# MKL28T7_CORE0 register map
Vendor: Freescale Semiconductor, Inc.; Series: Kinetis_L; File version: 1.6
CPU: CM0PLUS r0p0, little endian, no MPU, no FPU, VTOR, 2 interrupt priority bits
Registers are 32-bit, read-write, reset 0x0 unless marked. A register's access mark holds for its fields unless they carry their own. Offsets are from the block's base; [hi:lo] are bit positions; {n}, {i} and the like mark numbered series; 'fields as' and 'values as' point back to an identical list.

## TSI0 — Touch sense input
Base 0x40062000; register names take the prefix TSI0_
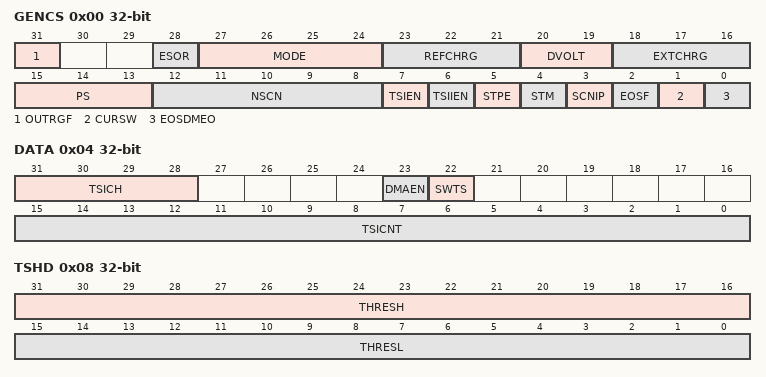
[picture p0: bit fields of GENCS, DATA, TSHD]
0x00 GENCS — TSI General Control and Status Register
  [31] OUTRGF — Out of Range Flag.
  [28] ESOR — End-of-scan or Out-of-Range Interrupt Selection
    0=Out-of-range interrupt is allowed; 1=End-of-scan interrupt is allowed
  [27:24] MODE — TSI analog modes setup and status bits.
    0=Set TSI in capacitive sensing(non-noise detection) mode; 4=Set TSI analog to work in single threshold noise detection mode and the frequency limitation circuit is disabled; 8=Set TSI analog to work in single threshold noise detection mode and the frequency limitation circuit is enabled to work in higher frequencies operations; 12=Set TSI analog to work in automatic noise detection mode
  [23:21] REFCHRG
    0=500 nA; 1=1 uA; 2=2 uA; 3=4 uA; 4=8 uA; 5=16 uA; 6=32 uA; 7=64 uA
  [20:19] DVOLT
    0=DV = 1.026 V; VP = 1.328 V; Vm = 0.302 V; 1=DV = 0.592 V; VP = 1.111 V; Vm = 0.519 V; 2=DV = 0.342 V; VP = 0.986 V; Vm = 0.644 V; 3=DV = 0.197 V; VP = 0.914 V; Vm = 0.716 V
  [18:16] EXTCHRG
    values as REFCHRG
  [15:13] PS
    0=Electrode Oscillator Frequency divided by 1; 1=Electrode Oscillator Frequency divided by 2; 2=Electrode Oscillator Frequency divided by 4; 3=Electrode Oscillator Frequency divided by 8; 4=Electrode Oscillator Frequency divided by 16; 5=Electrode Oscillator Frequency divided by 32; 6=Electrode Oscillator Frequency divided by 64; 7=Electrode Oscillator Frequency divided by 128
  [12:8] NSCN
    0=Once per electrode; 1=Twice per electrode; {v}={v+1} times per electrode (v=2..31)
  [7] TSIEN — Touch Sensing Input Module Enable
    0=TSI module disabled; 1=TSI module enabled
  [6] TSIIEN — Touch Sensing Input Interrupt Enable
    0=TSI interrupt is disabled; 1=TSI interrupt is enabled
  [5] STPE — TSI STOP Enable
    0=TSI is disabled when MCU goes into low power mode; 1=Allows TSI to continue running in all low power modes
  [4] STM — Scan Trigger Mode
    0=Software trigger scan; 1=Hardware trigger scan
  [3] SCNIP ro — Scan In Progress Status
    0=No scan in progress; 1=Scan in progress
  [2] EOSF — End of Scan Flag
    0=Scan not complete; 1=Scan complete
  [1] CURSW
    0=The current source pair are not swapped; 1=The current source pair are swapped
  [0] EOSDMEO — End-of-Scan DMA Transfer Request Enable Only
    0=Do not enable the End-of-Scan DMA transfer request only. Depending on ESOR state, either Out-of-Range or End-of-Scan can trigger a DMA transfer request and interrupt.; 1=Only the End-of-Scan event can trigger a DMA transfer request. The Out-of-Range event only and always triggers an interrupt if TSIIE is set.
0x04 DATA — TSI DATA Register
  [31:28] TSICH
    {v}=Channel {v} (v=0..15)
  [23] DMAEN — DMA Transfer Enabled
    0=Interrupt is selected when the interrupt enable bit is set and the corresponding TSI events assert; 1=DMA transfer request is selected when the interrupt enable bit is set and the corresponding TSI events assert
  [22] SWTS wo — Software Trigger Start
    0=No effect; 1=Start a scan to determine which channel is specified by TSI_DATA[TSICH]
  [15:0] TSICNT ro — TSI Conversion Counter Value
0x08 TSHD — TSI Threshold Register
  [31:16] THRESH — TSI Wakeup Channel High-threshold
  [15:0] THRESL — TSI Wakeup Channel Low-threshold

## DAC0 — 12-Bit Digital-to-Analog Converter
Base 0x4006A000; register names take the prefix DAC0_
{0x0+2i} DAT{i}L (i=0..15) 8-bit — DAC Data Low Register
  [7:0] DATA0
{0x1+2i} DAT{i}H (i=0..15) 8-bit — DAC Data High Register
  [3:0] DATA1
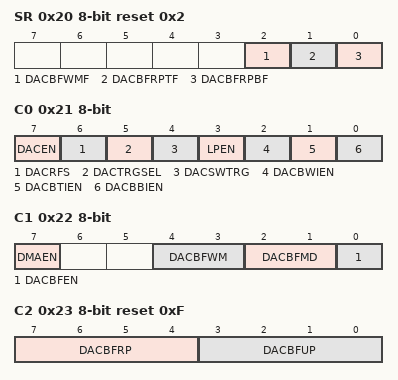
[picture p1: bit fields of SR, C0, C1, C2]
0x20 SR 8-bit reset 0x2 — DAC Status Register
  [2] DACBFWMF — DAC Buffer Watermark Flag
    0=The DAC buffer read pointer has not reached the watermark level; 1=The DAC buffer read pointer has reached the watermark level
  [1] DACBFRPTF — DAC Buffer Read Pointer Top Position Flag
    0=The DAC buffer read pointer is not zero; 1=The DAC buffer read pointer is zero
  [0] DACBFRPBF — DAC Buffer Read Pointer Bottom Position Flag
    0=The DAC buffer read pointer is not equal to C2[DACBFUP]; 1=The DAC buffer read pointer is equal to C2[DACBFUP]
0x21 C0 8-bit — DAC Control Register
  [7] DACEN — DAC Enable
    0=The DAC system is disabled; 1=The DAC system is enabled
  [6] DACRFS — DAC Reference Select
    0=The DAC selects DACREF_1 as the reference voltage; 1=The DAC selects DACREF_2 as the reference voltage
  [5] DACTRGSEL — DAC Trigger Select
    0=The DAC hardware trigger is selected; 1=The DAC software trigger is selected
  [4] DACSWTRG wo — DAC Software Trigger
    0=The DAC soft trigger is not valid; 1=The DAC soft trigger is valid
  [3] LPEN — DAC Low Power Control
    0=High-Power mode; 1=Low-Power mode
  [2] DACBWIEN — DAC Buffer Watermark Interrupt Enable
    0=The DAC buffer watermark interrupt is disabled; 1=The DAC buffer watermark interrupt is enabled
  [1] DACBTIEN — DAC Buffer Read Pointer Top Flag Interrupt Enable
    0=The DAC buffer read pointer top flag interrupt is disabled; 1=The DAC buffer read pointer top flag interrupt is enabled
  [0] DACBBIEN — DAC Buffer Read Pointer Bottom Flag Interrupt Enable
    0=The DAC buffer read pointer bottom flag interrupt is disabled; 1=The DAC buffer read pointer bottom flag interrupt is enabled
0x22 C1 8-bit — DAC Control Register 1
  [7] DMAEN — DMA Enable Select
    0=DMA is disabled; 1=DMA is enabled. When DMA is enabled, the DMA request will be generated by original interrupts. The interrupts will not be presented on this module at the same time.
  [4:3] DACBFWM — DAC Buffer Watermark Select
    0=In normal mode, 1 word . In FIFO mode, 2 or less than 2 data remaining in FIFO will set watermark status bit.; 1=In normal mode, 2 words . In FIFO mode, Max/4 or less than Max/4 data remaining in FIFO will set watermark status bit.; 2=In normal mode, 3 words . In FIFO mode, Max/2 or less than Max/2 data remaining in FIFO will set watermark status bit.; 3=In normal mode, 4 words . In FIFO mode, Max-2 or less than Max-2 data remaining in FIFO will set watermark status bit.
  [2:1] DACBFMD — DAC Buffer Work Mode Select
    0=Normal mode; 1=Swing mode; 2=One-Time Scan mode; 3=FIFO mode
  [0] DACBFEN — DAC Buffer Enable
    0=Buffer read pointer is disabled. The converted data is always the first word of the buffer.; 1=Buffer read pointer is enabled. The converted data is the word that the read pointer points to. It means converted data can be from any word of the buffer.
0x23 C2 8-bit reset 0xF — DAC Control Register 2
  [7:4] DACBFRP — DAC Buffer Read Pointer
  [3:0] DACBFUP — DAC Buffer Upper Limit
